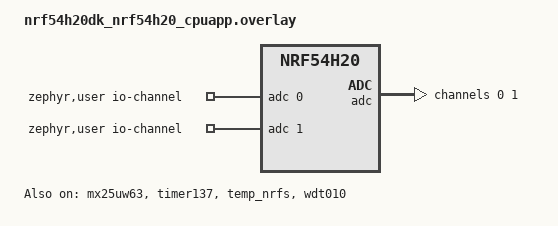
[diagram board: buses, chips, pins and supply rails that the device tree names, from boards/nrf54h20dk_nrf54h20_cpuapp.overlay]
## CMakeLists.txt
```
#
# Copyright (c) 2024 Nordic Semiconductor ASA
#
# SPDX-License-Identifier: LicenseRef-Nordic-5-Clause
#

cmake_minimum_required(VERSION 3.20.0)
find_package(Zephyr REQUIRED HINTS $ENV{ZEPHYR_BASE})
project(periph_stress)

FILE(GLOB app_sources src/*.c)
target_sources(app PRIVATE ${app_sources})
```

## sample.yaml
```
sample:
  name: Peripheral stress test

common:
  depends_on: adc gpio i2c pwm spi watchdog
  tags: drivers spi sensors ci_tests_benchmarks_peripheral_load
  harness: console

tests:
  sample.benchmarks.peripheral_stress_test.nrf54h:
    filter: not CONFIG_COVERAGE
    harness_config:
      fixture: pca63566
      type: multi_line
      ordered: false
      regex:
        - ".*Accelerometer thread has completed"
        - ".*ADC thread has completed"
        - ".*BME680 thread has completed"
        - ".*CAN thread has completed"
        - ".*Counter thread has completed"
        - ".*Flash thread has completed"
        - ".*GPIO thread has completed"
        - ".*PWM thread has completed"
        - ".*TEMP thread has completed"
        - ".*Timer thread has completed"
        - ".*WDT thread has completed"
        - ".*CPU load thread has completed"
        - ".*Clock thread has completed"
        - ".*all \\d{1,} threads have completed"
    extra_args:
      - SHIELD=pca63566
    platform_allow: nrf54h20dk/nrf54h20/cpuapp
    integration_platforms:
      - nrf54h20dk/nrf54h20/cpuapp

  sample.benchmarks.peripheral_stress_test.nrf54l:
    filter: not CONFIG_COVERAGE
    harness_config:
      fixture: pca63565
      type: multi_line
      ordered: false
      regex:
        - ".*Accelerometer thread has completed"
        - ".*ADC thread has completed"
        - ".*BME680 thread has completed"
        - ".*Counter thread has completed"
        - ".*Flash thread has completed"
        - ".*GPIO thread has completed"
        - ".*I2S thread has completed"
        - ".*PWM thread has completed"
        - ".*TEMP thread has completed"
        - ".*Timer thread has completed"
        - ".*WDT thread has completed"
        - ".*CPU load thread has completed"
        - ".*all \\d{1,} threads have completed"
    extra_args:
      - SHIELD=pca63565
    platform_allow: nrf54l15dk/nrf54l15/cpuapp
    integration_platforms:
      - nrf54l15dk/nrf54l15/cpuapp
```

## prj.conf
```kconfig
CONFIG_LOG=y

CONFIG_SENSOR=y
CONFIG_ADC=y
CONFIG_CAN=y
CONFIG_COUNTER=y
CONFIG_FLASH=y
CONFIG_GPIO=y
CONFIG_I2S=y
CONFIG_PWM=y
CONFIG_WATCHDOG=y
```

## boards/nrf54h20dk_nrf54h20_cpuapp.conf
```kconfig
CONFIG_CLOCK_CONTROL=y
```

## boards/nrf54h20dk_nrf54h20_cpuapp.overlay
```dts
/*
 * Copyright (c) 2024 Nordic Semiconductor ASA
 *
 * SPDX-License-Identifier: LicenseRef-Nordic-5-Clause
 */

/ {
	aliases {
		test-counter = &timer137;
		watchdog0 = &wdt010;
	};

	zephyr,user {
		io-channels = <&adc 0>, <&adc 1>;
	};
};

&adc {
	#address-cells = <1>;
	#size-cells = <0>;

	channel@0 {
		reg = <0>;
		zephyr,gain = "ADC_GAIN_1_2";
		zephyr,reference = "ADC_REF_INTERNAL";
		zephyr,acquisition-time = <ADC_ACQ_TIME(ADC_ACQ_TIME_MICROSECONDS, 10)>;
		zephyr,input-positive = <NRF_SAADC_AIN4>;
		zephyr,resolution = <10>;
	};

	channel@1 {
		reg = <1>;
		zephyr,gain = "ADC_GAIN_2";
		zephyr,reference = "ADC_REF_EXTERNAL0";
		zephyr,acquisition-time = <ADC_ACQ_TIME(ADC_ACQ_TIME_MICROSECONDS, 10)>;
		zephyr,input-positive = <NRF_SAADC_AIN5>;
		zephyr,resolution = <10>;
	};
};

&mx25uw63 {
	status = "okay";
};

&timer137 {
	status = "okay";
	prescaler = <4>;
};

temp_sensor: &temp_nrfs {
	status = "okay";
};

&wdt010 {
	status = "okay";
};
```

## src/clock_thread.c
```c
/*
 * Copyright (c) 2024 Nordic Semiconductor ASA
 *
 * SPDX-License-Identifier: LicenseRef-Nordic-5-Clause
 */
#ifdef CONFIG_CLOCK_CONTROL_NRF2
#include "common.h"

#include <zephyr/logging/log.h>
LOG_MODULE_REGISTER(clock, LOG_LEVEL_INF);

#include <zephyr/devicetree.h>
#include <zephyr/devicetree/clocks.h>
#include <zephyr/drivers/clock_control/nrf_clock_control.h>
#include <zephyr/kernel.h>

struct test_clk_context {
	const struct device *clk_dev;
	const struct nrf_clock_spec *clk_specs;
	size_t clk_specs_size;
};

const struct nrf_clock_spec test_clk_specs_hsfll[] = {
	{
		.frequency = MHZ(128),
		.accuracy = 0,
		.precision = NRF_CLOCK_CONTROL_PRECISION_DEFAULT,
	},
	{
		.frequency = MHZ(320),
		.accuracy = 0,
		.precision = NRF_CLOCK_CONTROL_PRECISION_DEFAULT,
	},
	{
		.frequency = MHZ(64),
		.accuracy = 0,
		.precision = NRF_CLOCK_CONTROL_PRECISION_DEFAULT,
	},
};

const struct nrf_clock_spec test_clk_specs_fll16m[] = {
	{
		.frequency = MHZ(16),
		.accuracy = 20000,
		.precision = NRF_CLOCK_CONTROL_PRECISION_DEFAULT,
	},
	{
		.frequency = MHZ(16),
		.accuracy = 5020,
		.precision = NRF_CLOCK_CONTROL_PRECISION_DEFAULT,
	},
	{
		.frequency = MHZ(16),
		.accuracy = 30,
		.precision = NRF_CLOCK_CONTROL_PRECISION_DEFAULT,
	},
};

static const struct test_clk_context fll16m_test_clk_contexts[] = {
	{
		.clk_dev = DEVICE_DT_GET(DT_NODELABEL(fll16m)),
		.clk_specs = test_clk_specs_fll16m,
		.clk_specs_size = ARRAY_SIZE(test_clk_specs_fll16m),
	},
};

static const struct test_clk_context cpuapp_hsfll_test_clk_contexts[] = {
	{
		.clk_dev = DEVICE_DT_GET(DT_NODELABEL(cpuapp_hsfll)),
		.clk_specs = test_clk_specs_hsfll,
		.clk_specs_size = ARRAY_SIZE(test_clk_specs_hsfll),
	},
};

const struct nrf_clock_spec test_clk_specs_lfclk[] = {
	{
		.frequency = 32768,
		.accuracy = 0,
		.precision = NRF_CLOCK_CONTROL_PRECISION_DEFAULT,
	},
	{
		.frequency = 32768,
		.accuracy = 20,
		.precision = NRF_CLOCK_CONTROL_PRECISION_DEFAULT,
	},
	{
		.frequency = 32768,
		.accuracy = 20,
		.precision = NRF_CLOCK_CONTROL_PRECISION_HIGH,
	},
};

static const struct test_clk_context lfclk_test_clk_contexts[] = {
	{
		.clk_dev = DEVICE_DT_GET(DT_NODELABEL(lfclk)),
		.clk_specs = test_clk_specs_lfclk,
		.clk_specs_size = ARRAY_SIZE(test_clk_specs_lfclk),
	},
};

static void test_request_release_clock_spec(const struct device *clk_dev,
					    const struct nrf_clock_spec *clk_spec)
{
	int ret = 0;
	int res = 0;
	struct onoff_client cli;
	uint32_t rate;

	LOG_INF("Clock under test: %s", clk_dev->name);
	sys_notify_init_spinwait(&cli.notify);
	ret = nrf_clock_control_request(clk_dev, clk_spec, &cli);
	LOG_INF("Clock control request return value: %d", ret);
	if (ret != 0) {
		LOG_ERR("Clock control request failed");
		atomic_inc(&completed_threads);
		return;
	}
	do {
		ret = sys_notify_fetch_result(&cli.notify, &res);
		k_yield();
	} while (ret == -EAGAIN);
	LOG_INF("Clock control request response code: %d", res);
	if (res != 0) {
		LOG_ERR("Wrong clock control request response code");
		atomic_inc(&completed_threads);
		return;
	}
	ret = clock_control_get_rate(clk_dev, NULL, &rate);
	LOG_INF("Clock control get rate response code: %d", ret);
	if (ret != 0) {
		LOG_ERR("Clock control get rate failed");
		atomic_inc(&completed_threads);
		return;
	}
	if (rate != clk_spec->frequency) {
		LOG_ERR("Invalid rate: %d", rate);
		atomic_inc(&completed_threads);
		return;
	}
	k_msleep(1000);
	ret = nrf_clock_control_release(clk_dev, clk_spec);
	if (ret != ONOFF_STATE_ON) {
		LOG_ERR("Clock control release failed");
		atomic_inc(&completed_threads);
		return;
	}
}

static void test_clock_control_request(const struct test_clk_context *clk_contexts,
				       size_t contexts_size)
{
	const struct test_clk_context *clk_context;
	size_t clk_specs_size;
	const struct device *clk_dev;
	const struct nrf_clock_spec *clk_spec;

	for (size_t i = 0; i < contexts_size; i++) {
		clk_context = &clk_contexts[i];
		clk_specs_size = clk_context->clk_specs_size;

		for (size_t u = 0; u < clk_specs_size; u++) {
			clk_dev = clk_context->clk_dev;
			clk_spec = &clk_context->clk_specs[u];

			LOG_INF("Applying clock (%s) spec: frequency %d, accuracy %d, precision "
				"%d",
				clk_dev->name, clk_spec->frequency, clk_spec->accuracy,
				clk_spec->precision);
			test_request_release_clock_spec(clk_dev, clk_spec);
		}
	}
}

/* Clock thread */
static void clock_thread(void *arg1, void *arg2, void *arg3)
{
	ARG_UNUSED(arg1);
	ARG_UNUSED(arg2);
	ARG_UNUSED(arg3);

	atomic_inc(&started_threads);

	k_msleep(100);
	test_clock_control_request(cpuapp_hsfll_test_clk_contexts,
				   ARRAY_SIZE(cpuapp_hsfll_test_clk_contexts));

	test_clock_control_request(fll16m_test_clk_contexts, ARRAY_SIZE(fll16m_test_clk_contexts));

	test_clock_control_request(lfclk_test_clk_contexts, ARRAY_SIZE(lfclk_test_clk_contexts));

	LOG_INF("Clock thread has completed");

	atomic_inc(&completed_threads);
}

K_THREAD_DEFINE(thread_clock_id, CLOCK_THREAD_STACKSIZE, clock_thread, NULL, NULL, NULL,
		K_PRIO_PREEMPT(CLOCK_THREAD_PRIORITY), 0, 0);
#endif
```

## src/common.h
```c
/*
 * Copyright (c) 2024 Nordic Semiconductor ASA
 *
 * SPDX-License-Identifier: LicenseRef-Nordic-5-Clause
 */

#ifndef PERIPHERAL_STRESS_TEST_H
#define PERIPHERAL_STRESS_TEST_H

#include <zephyr/kernel.h>
#include <zephyr/device.h>

/* Thread status */
extern atomic_t started_threads;
extern atomic_t completed_threads;

/* Accelerator readout via SPI: */
#define ACCEL_THREAD_COUNT_MAX		(40)
#define ACCEL_THREAD_OVERSAMPLING	(3)
#define ACCEL_THREAD_STACKSIZE		(1024)
#define ACCEL_THREAD_PRIORITY		(5)
#define ACCEL_THREAD_SLEEP			(200)

/* ADC thread: */
#define ADC_THREAD_COUNT_MAX	(40)
#define ADC_THREAD_OVERSAMPLING (3)
#define ADC_THREAD_STACKSIZE	(1024)
#define ADC_THREAD_PRIORITY		(5)
#define ADC_THREAD_SLEEP		(200)

/* BME680 environment sensor readout via I2C: */
#define BME680_THREAD_COUNT_MAX		(40)
#define BME680_THREAD_OVERSAMPLING	(2)
#define BME680_THREAD_STACKSIZE		(1024)
#define BME680_THREAD_PRIORITY		(5)
#define BME680_THREAD_SLEEP			(200)

/* CAN thread: */
#define CAN_THREAD_COUNT_MAX	(40)
#define CAN_THREAD_STACKSIZE	(1024)
#define CAN_THREAD_PRIORITY		(5)
#define CAN_THREAD_SLEEP		(200)

/* Counter thread: */
#define COUNTER_THREAD_COUNT_MAX	(40)
#define COUNTER_THREAD_STACKSIZE	(512)
#define COUNTER_THREAD_PRIORITY		(5)
#define COUNTER_THREAD_PERIOD		(200)

/* FLASH thread: */
#define FLASH_THREAD_COUNT_MAX	(40)
#define FLASH_THREAD_STACKSIZE	(2048)
#define FLASH_THREAD_PRIORITY	(5)
#define FLASH_THREAD_SLEEP		(200)

/* GPIO thread: */
#define GPIO_THREAD_COUNT_MAX	(40)
#define GPIO_THREAD_STACKSIZE	(512)
#define GPIO_THREAD_PRIORITY	(5)
#define GPIO_THREAD_SLEEP		(200)

/* I2S thread: */
#define I2S_THREAD_COUNT_MAX	(40)
#define I2S_THREAD_STACKSIZE	(1024)
#define I2S_THREAD_PRIORITY		(5)
#define I2S_THREAD_SLEEP		(200)

/* PWM thread: */
#define PWM_THREAD_COUNT_MAX	(40)
#define PWM_THREAD_OVERSAMPLING	(10)
#define PWM_THREAD_STACKSIZE	(512)
#define PWM_THREAD_PRIORITY		(5)
#define PWM_THREAD_SLEEP		(200)

/* TEMP thread: */
#define TEMP_THREAD_COUNT_MAX	(40)
#define TEMP_THREAD_STACKSIZE	(512)
#define TEMP_THREAD_PRIORITY	(5)
#define TEMP_THREAD_PERIOD		(200)

/* Timer thread: */
#define TIMER_THREAD_COUNT_MAX	(40)
#define TIMER_THREAD_STACKSIZE	(512)
#define TIMER_THREAD_PRIORITY	(5)
#define TIMER_THREAD_PERIOD		(200)

/* Watchdog thread: */
#define WDT_THREAD_COUNT_MAX	(40)
#define WDT_THREAD_STACKSIZE	(512)
#define WDT_THREAD_PRIORITY		(4)
#define WDT_THREAD_PERIOD		(200)
#define WDT_WINDOW_MAX			(2 * WDT_THREAD_PERIOD)
#define WDT_TAG					(0x12345678U)

/* Clock thread: */
#define CLOCK_THREAD_STACKSIZE	(512)
#define CLOCK_THREAD_PRIORITY	(4)


/* Busy load thread: */
#define LOAD_THREAD_STACKSIZE	(1024)
#define LOAD_THREAD_PRIORITY	(CONFIG_NUM_PREEMPT_PRIORITIES - 1)
#define LOAD_THREAD_DURATION	(ACCEL_THREAD_SLEEP * (ACCEL_THREAD_COUNT_MAX + 2))


#endif
```

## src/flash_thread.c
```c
/*
 * Copyright (c) 2024 Nordic Semiconductor ASA
 *
 * SPDX-License-Identifier: LicenseRef-Nordic-5-Clause
 */

#include <zephyr/logging/log.h>
LOG_MODULE_REGISTER(flash_thd, LOG_LEVEL_INF);

#include <zephyr/drivers/flash.h>
#include <zephyr/devicetree.h>
#include "common.h"

#if DT_HAS_COMPAT_STATUS_OKAY(jedec_spi_nor)
#define FLASH_NODE DT_COMPAT_GET_ANY_STATUS_OKAY(jedec_spi_nor)
#elif DT_HAS_COMPAT_STATUS_OKAY(nordic_qspi_nor)
#define FLASH_NODE DT_COMPAT_GET_ANY_STATUS_OKAY(nordic_qspi_nor)
#else
#error Unsupported flash driver
#define FLASH_NODE DT_INVALID_NODE
#endif

#define TEST_AREA_OFFSET	(0xff000)
#define EXPECTED_SIZE		(512)

static const struct device *const flash_dev = DEVICE_DT_GET(FLASH_NODE);

/* Flash thread */
static void flash_thread(void *arg1, void *arg2, void *arg3)
{
	ARG_UNUSED(arg1);
	ARG_UNUSED(arg2);
	ARG_UNUSED(arg3);

	int ret;
	uint8_t buf[EXPECTED_SIZE];

	atomic_inc(&started_threads);

	if (!device_is_ready(flash_dev)) {
		LOG_ERR("Device %s is not ready.", flash_dev->name);
		atomic_inc(&completed_threads);
		return;
	}

	for (int i = 0; i < FLASH_THREAD_COUNT_MAX; i++) {
		/* Read external memory */
		ret = flash_read(flash_dev, TEST_AREA_OFFSET, buf, EXPECTED_SIZE);
		if (ret < 0) {
			LOG_ERR("flash_read() failed (%d)", ret);
			atomic_inc(&completed_threads);
			return;
		}
		LOG_INF("flash_read() #%d done", i);

		k_msleep(FLASH_THREAD_SLEEP);
	}
	LOG_INF("Flash thread has completed");

	atomic_inc(&completed_threads);
}

K_THREAD_DEFINE(thread_flash_id, FLASH_THREAD_STACKSIZE, flash_thread, NULL, NULL, NULL,
	K_PRIO_PREEMPT(FLASH_THREAD_PRIORITY), 0, 0);
```
